# ExynosT100 register map
Vendor: SAMSUNG System LSI; Series: ARMCM4F; File version: 0.1
CPU: CM4 r1p0, little endian, MPU, FPU, 3 interrupt priority bits
Registers are 32-bit, read-write, reset 0x0 unless marked. A register's access mark holds for its fields unless they carry their own. Offsets are from the block's base; [hi:lo] are bit positions; {n}, {i} and the like mark numbered series.

## QSPI — Flash controller
Base 0x40024000
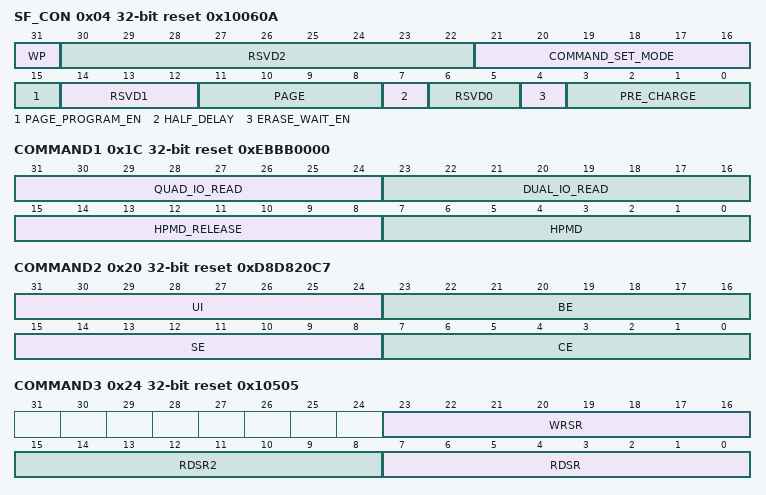
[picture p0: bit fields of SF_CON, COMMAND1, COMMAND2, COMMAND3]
0x04 SF_CON reset 0x10060A — Control Register
  [31] WP — Write protection 0 = Enable 1 = Disable
  [30:22] RSVD2 ro
  [21:16] COMMAND_SET_MODE — Updates command set: COMMAND1, COMMAND2, COMMAND3, COMMAND4, and COMMAND5 6'b100000 = Mode 0 command set 6'b010000 = Mode 1 command set (default) 6'b001000 = Mode 2 command set 6'b000100 = Mode 3 command set 6'b000010 = Mode 4 command set 6'b000001 = Mode 5 command set If multiple bits are 1, MSB has a priority.
  [15] PAGE_PROGRAM_EN ro — GPage programing mode 0 = Byte programing 1 = Page programing
  [14:12] RSVD1 ro
  [11:8] PAGE — Bytes per page 0 = 4 bytes 1 = 8 bytes 2 = 16 bytes 3 = 32 bytes 4 = 64 bytes 5 = 128 bytes 6 = 256 bytes 7 = Reserved
  [7] HALF_DELAY — Input data sample with half frequency delay If data output delay is more than half cycle of SCLK, set this bit to 1.
  [6:5] RSVD0 ro
  [4] ERASE_WAIT_EN — Check the busy status after the erase command 0 = Does not check the busy status 1 = Check the busy status
  [3:0] PRE_CHARGE — Retains the CS as high Pre-charge time: (PRE_CHARGE + 1) * (1/sfclk)
0x10 ERASE_ADDRSSS reset 0xFFFFFFFF — Control Register
  [31:0] EraseAddress
0x18 USER_COMMAND
  [31:0] USER_COMMAND — When you want to use user-defined command, write this field [31:24] = CS drive [23:16] = SPICLK drive [15:8] = SI drive [7:0] = No effect When you read this field, SO sampled data is read. The data is double sampled when SPICLK is toggled.
0x1C COMMAND1 reset 0xEBBB0000
  [31:24] QUAD_IO_READ — Quad I/O
  [23:16] DUAL_IO_READ — Dual I/O
  [15:8] HPMD_RELEASE — High performance release
  [7:0] HPMD — High performance
0x20 COMMAND2 reset 0xD8D820C7
  [31:24] UI — User instruction
  [23:16] BE — Block erase
  [15:8] SE — Sector erase
  [7:0] CE — Chip erase
0x24 COMMAND3 reset 0x10505
  [23:16] WRSR — Write status register
  [15:8] RDSR2 — Read status register 2 Use this register only when you set FLASH_IO_MODE to read quad_enable flag in status register of external devices.
  [7:0] RDSR — Read status register
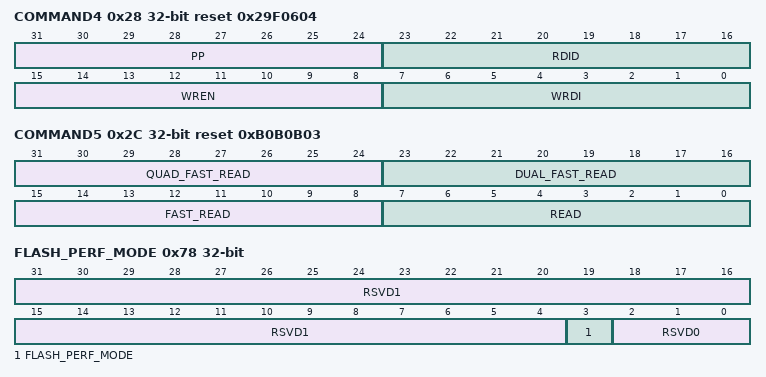
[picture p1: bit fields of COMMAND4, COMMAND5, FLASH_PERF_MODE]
0x28 COMMAND4 reset 0x29F0604
  [31:24] PP — Page program
  [23:16] RDID — Read ID
  [15:8] WREN — Write enable
  [7:0] WRDI — Write disable
0x2C COMMAND5 reset 0xB0B0B03
  [31:24] QUAD_FAST_READ ro, [23:16] DUAL_FAST_READ, [15:8] FAST_READ, [7:0] READ
0x59 USER_INSTRUCTION — User Program Instruction Transfer
  [7:0] USER_INSTRUCTION wo — If you write this address with another address, then COMMAMD2.UI is sent though SI pin Use only instructions without data. Use only during normal read mode.
0x5E SE — Sector Erase
  [7:0] SECTOR_ERASE wo — If you write this address with dummy data, then COMMAMD2.SE is sent though SI pin
0x74 FLASH_IO_MODE
  [3:0] FLASH_IO_MODE — 0x0 = Normal mode (COMMAND5.READ is sent through SI pin) 0x1 = Fast mode (COMMAND5.FAST_READ is sent through SI pin) 0x2 = Dual fast mode (COMMAND5.DUAL_FAST_READ is sent through SI pin) 0x4 = Quad fast mode (COMMAND5.QUAD_FAST_READ is sent through SI pin) 0x8 = Read mode (COMMAND5.READ is sent through SI pin) If COMMAND_SET_MODE is 6'b10_0000, then controller sets or resets quad_enable flag which is expected in status register[9] of external devices. If COMMAND_SET_MODE is 6'b01_0000, then controller sets or resets quad_enable flag which is expected in status register[6] of external devices.
0x78 FLASH_PERF_MODE — Flash Performance Mode
  [31:4] RSVD1 ro
  [3] FLASH_PERF_MODE wo — 0 = Command of COMMAND5 is sent through SI pin 1 = Command of COMMAND1 is sent through SI pin If FLASH_IO_MODE is 0x2, then COMMAND1.DUAL_IO_READ is sent through SI pin If FLASH_IO_MODE is 0x4, then COMMAND1.QUAD_IO_READ is sent through SI pin. This bit is valid when FLASH_IO_MODE is 0x2 or 0x4. If you want to use FAST_READ, DUAL_FAST_READ, and QUAD_FAST_READ instructions, then this bit must be 0.
  [2:0] RSVD0 ro
0xAC RDID — Flash Vendor ID
  [7:0] FLASH_VENDOR_ID ro — If you read this address, then COMMAMD4.RDID is sent through SI pin and you can read manufacture ID and device ID This register must be read with word access. [31:24] = N/A [23:16] = Third output byte of device (Capacity) [15:8] = Second output byte of device (Memory Type) [7:0] = First output byte of device (Manufacture ID)
0xBE BE 8-bit — Block Erase
  [7:0] BLOCK_ERASE ro — If you write this address with dummy data, then COMMAMD2.BE is sent through SI pin
0xCE CE 8-bit — Chip Erase
  [7:0] CHIP_ERASE wo — If you write this address with dummy data, then COMMAMD3.CE is sent through SI pin
0xDC RDSR 8-bit — Read Status Register
  [7:0] READ_STATUS_REGISTER ro — If you give read access to this address, then COMMAMD3.RDSR is sent through SI pin
0xDD WRDI 8-bit — Write Disable
  [7:0] WRITE_DISABLE wo — If you write this address with dummy data, then COMMAMD3.WRDI is sent though SI pin
0xDE WRSR 16-bit — Write Status Register
  [15:0] WRITE_STATUS_REGISTER wo — If you write this address with valid data, then COMMAMD3.WRSR is sent through SI pin Write with byte access: 1 byte is sent through SI pin. Write with half-word access: 2 byte is sent through SI pin. Sequence of {[7:0] and [15:8]}
0xEE WREN 8-bit — Write Enable
  [7:0] WRTIE_ENABLE wo — If you write this address with dummy data, then COMMAMD4.WREN is sent through SI pin
